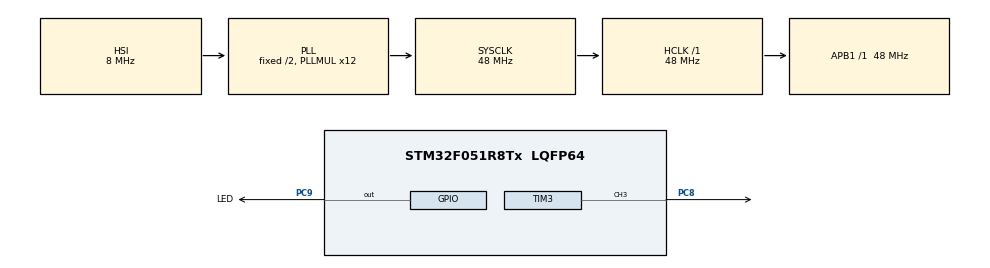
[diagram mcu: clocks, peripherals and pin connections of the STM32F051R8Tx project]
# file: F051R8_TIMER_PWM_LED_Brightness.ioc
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Mcu.Family=STM32F0
PC9.GPIO_Label=LED
NVIC.TIM6_DAC_IRQn=true\:0\:0\:false\:false\:true\:true\:true
PA14.GPIO_Label=SWCLK
TIM6.Prescaler=480-1
PC8.Signal=S_TIM3_CH3
VP_TIM6_VS_ClockSourceINT.Mode=Enable_Timer
SH.S_TIM3_CH3.0=TIM3_CH3,PWM Generation3 CH3
RCC.SYSCLKSource=RCC_SYSCLKSOURCE_PLLCLK
ProjectManager.StackSize=0x400
PA13.Signal=SYS_SWDIO
TIM3.Channel-PWM\ Generation3\ CH3=TIM_CHANNEL_3
ProjectManager.TargetToolchain=STM32CubeIDE
RCC.HCLKFreq_Value=48000000
TIM3.Period=1000-1
RCC.AHBFreq_Value=48000000
TIM3.Pulse-PWM\ Generation3\ CH3=250-1
board=STM32F0DISCOVERY
RCC.PLLMUL=RCC_PLL_MUL12
PA14.Mode=Serial_Wire
TIM3.Prescaler=480-1
TIM6.Period=1000-1
PA13.Mode=Serial_Wire
Mcu.Name=STM32F051R8Tx
PA13.GPIO_Label=SWDIO
RCC.SYSCLKFreq_VALUE=48000000
Mcu.Package=LQFP64
PA14.Signal=SYS_SWCLK
ProjectManager.HeapSize=0x200
RCC.APB1TimFreq_Value=48000000
PC9.Signal=GPIO_Output
RCC.APB1Freq_Value=48000000
VP_TIM3_VS_ClockSourceINT.Mode=Internal

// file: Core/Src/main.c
/* USER CODE BEGIN Header */
/**
  ******************************************************************************
  * @file           : main.c
  * @brief          : Main program body
  ******************************************************************************
  * @attention
  *
  * <h2><center>&copy; Copyright (c) 2021 STMicroelectronics.
  * All rights reserved.</center></h2>
  *
  * This software component is licensed by ST under BSD 3-Clause license,
  * the "License"; You may not use this file except in compliance with the
  * License. You may obtain a copy of the License at:
  *                        opensource.org/licenses/BSD-3-Clause
  *
  ******************************************************************************
  */
/* USER CODE END Header */
#include "main.h"

TIM_HandleTypeDef htim3;
TIM_HandleTypeDef htim6;

/* USER CODE BEGIN PV */
uint16_t dutyCycle = 0;
int16_t dutyInc = 1;
/* USER CODE END PV */

void SystemClock_Config(void);
static void MX_GPIO_Init(void);
static void MX_TIM3_Init(void);
static void MX_TIM6_Init(void);

/* USER CODE BEGIN 0 */
void HAL_TIM_PeriodElapsedCallback(TIM_HandleTypeDef *htim) {
  if(dutyCycle >= __HAL_TIM_GET_AUTORELOAD(&htim3)) {
    dutyInc = -1;
  } else if(dutyCycle == 0) {
    dutyInc = +1;
  }
  dutyCycle += dutyInc;
  __HAL_TIM_SET_COMPARE(&htim3, TIM_CHANNEL_3, dutyCycle);
}
/* USER CODE END 0 */

int main(void)
{

  /* MCU Configuration--------------------------------------------------------*/

  /* Reset of all peripherals, Initializes the Flash interface and the Systick. */
  HAL_Init();

  /* Configure the system clock */
  SystemClock_Config();

  /* Initialize all configured peripherals */
  MX_GPIO_Init();
  MX_TIM3_Init();
  MX_TIM6_Init();

  /* Infinite loop */
  /* USER CODE BEGIN WHILE */
  dutyCycle = __HAL_TIM_GET_AUTORELOAD(&htim3);
  HAL_TIM_PWM_Start(&htim3, TIM_CHANNEL_3);
  HAL_TIM_Base_Start_IT(&htim6);
  while (1)
  {
    HAL_GPIO_TogglePin(LED_GPIO_Port, LED_Pin);
    HAL_Delay(1000);
    /* USER CODE END WHILE */

  }
}

void SystemClock_Config(void)
{
  RCC_OscInitTypeDef RCC_OscInitStruct = {0};
  RCC_ClkInitTypeDef RCC_ClkInitStruct = {0};

  /** Initializes the RCC Oscillators according to the specified parameters
  * in the RCC_OscInitTypeDef structure.
  */
  RCC_OscInitStruct.OscillatorType = RCC_OSCILLATORTYPE_HSI;
  RCC_OscInitStruct.HSIState = RCC_HSI_ON;
  RCC_OscInitStruct.HSICalibrationValue = RCC_HSICALIBRATION_DEFAULT;
  RCC_OscInitStruct.PLL.PLLState = RCC_PLL_ON;
  RCC_OscInitStruct.PLL.PLLSource = RCC_PLLSOURCE_HSI;
  RCC_OscInitStruct.PLL.PLLMUL = RCC_PLL_MUL12;
  RCC_OscInitStruct.PLL.PREDIV = RCC_PREDIV_DIV1;
  if (HAL_RCC_OscConfig(&RCC_OscInitStruct) != HAL_OK)
  {
    Error_Handler();
  }
  /** Initializes the CPU, AHB and APB buses clocks
  */
  RCC_ClkInitStruct.ClockType = RCC_CLOCKTYPE_HCLK|RCC_CLOCKTYPE_SYSCLK
                              |RCC_CLOCKTYPE_PCLK1;
  RCC_ClkInitStruct.SYSCLKSource = RCC_SYSCLKSOURCE_PLLCLK;
  RCC_ClkInitStruct.AHBCLKDivider = RCC_SYSCLK_DIV1;
  RCC_ClkInitStruct.APB1CLKDivider = RCC_HCLK_DIV1;

  if (HAL_RCC_ClockConfig(&RCC_ClkInitStruct, FLASH_LATENCY_1) != HAL_OK)
  {
    Error_Handler();
  }
}

static void MX_TIM3_Init(void)
{

  TIM_ClockConfigTypeDef sClockSourceConfig = {0};
  TIM_MasterConfigTypeDef sMasterConfig = {0};
  TIM_OC_InitTypeDef sConfigOC = {0};

  htim3.Instance = TIM3;
  htim3.Init.Prescaler = 480-1;
  htim3.Init.CounterMode = TIM_COUNTERMODE_UP;
  htim3.Init.Period = 1000-1;
  htim3.Init.ClockDivision = TIM_CLOCKDIVISION_DIV1;
  htim3.Init.AutoReloadPreload = TIM_AUTORELOAD_PRELOAD_DISABLE;
  if (HAL_TIM_Base_Init(&htim3) != HAL_OK)
  {
    Error_Handler();
  }
  sClockSourceConfig.ClockSource = TIM_CLOCKSOURCE_INTERNAL;
  if (HAL_TIM_ConfigClockSource(&htim3, &sClockSourceConfig) != HAL_OK)
  {
    Error_Handler();
  }
  if (HAL_TIM_PWM_Init(&htim3) != HAL_OK)
  {
    Error_Handler();
  }
  sMasterConfig.MasterOutputTrigger = TIM_TRGO_RESET;
  sMasterConfig.MasterSlaveMode = TIM_MASTERSLAVEMODE_DISABLE;
  if (HAL_TIMEx_MasterConfigSynchronization(&htim3, &sMasterConfig) != HAL_OK)
  {
    Error_Handler();
  }
  sConfigOC.OCMode = TIM_OCMODE_PWM1;
  sConfigOC.Pulse = 250-1;
  sConfigOC.OCPolarity = TIM_OCPOLARITY_HIGH;
  sConfigOC.OCFastMode = TIM_OCFAST_DISABLE;
  if (HAL_TIM_PWM_ConfigChannel(&htim3, &sConfigOC, TIM_CHANNEL_3) != HAL_OK)
  {
    Error_Handler();
  }
  HAL_TIM_MspPostInit(&htim3);

}

static void MX_TIM6_Init(void)
{

  TIM_MasterConfigTypeDef sMasterConfig = {0};

  htim6.Instance = TIM6;
  htim6.Init.Prescaler = 480-1;
  htim6.Init.CounterMode = TIM_COUNTERMODE_UP;
  htim6.Init.Period = 1000-1;
  htim6.Init.AutoReloadPreload = TIM_AUTORELOAD_PRELOAD_DISABLE;
  if (HAL_TIM_Base_Init(&htim6) != HAL_OK)
  {
    Error_Handler();
  }
  sMasterConfig.MasterOutputTrigger = TIM_TRGO_RESET;
  sMasterConfig.MasterSlaveMode = TIM_MASTERSLAVEMODE_DISABLE;
  if (HAL_TIMEx_MasterConfigSynchronization(&htim6, &sMasterConfig) != HAL_OK)
  {
    Error_Handler();
  }

}

static void MX_GPIO_Init(void)
{
  GPIO_InitTypeDef GPIO_InitStruct = {0};

  /* GPIO Ports Clock Enable */
  __HAL_RCC_GPIOC_CLK_ENABLE();
  __HAL_RCC_GPIOA_CLK_ENABLE();

  /*Configure GPIO pin Output Level */
  HAL_GPIO_WritePin(LED_GPIO_Port, LED_Pin, GPIO_PIN_RESET);

  /*Configure GPIO pin : LED_Pin */
  GPIO_InitStruct.Pin = LED_Pin;
  GPIO_InitStruct.Mode = GPIO_MODE_OUTPUT_PP;
  GPIO_InitStruct.Pull = GPIO_NOPULL;
  GPIO_InitStruct.Speed = GPIO_SPEED_FREQ_LOW;
  HAL_GPIO_Init(LED_GPIO_Port, &GPIO_InitStruct);

}

void Error_Handler(void)
{
  __disable_irq();
  while (1)
  {
  }
}

/************************ (C) COPYRIGHT STMicroelectronics *****END OF FILE****/
